AUTOSAR XML (schema 4-0-3)
package /ComponentTypes
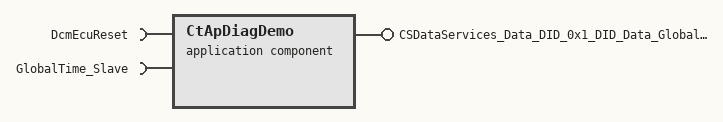
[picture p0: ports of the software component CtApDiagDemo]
  application sw component type CtApDiagDemo
    provide port CSDataServices_Data_DID_0x1_DID_Data_GlobalTime: server-com-spec{operation=ReadData, queue-length=1}, provided-interface=CSDataServices_Data_DID_0x1_DID_Data_GlobalTime
    require port DcmEcuReset: mode-switch-receiver-com-spec{enhanced-mode-api=false, supports-asynchronous-mode-switch=false}, required-interface=DcmEcuReset
    require port GlobalTime_Slave: required-interface=GlobalTime_Slave
    behavior CtApDiagDemo_InternalBehavior
  swc implementation CtApDiagDemo_Implementation: behavior=CtApDiagDemo_InternalBehavior
    code-descriptors:
      code Default: artifact-descriptors=autosar-engineering-object={short-label=Default, category=SWSRC}
